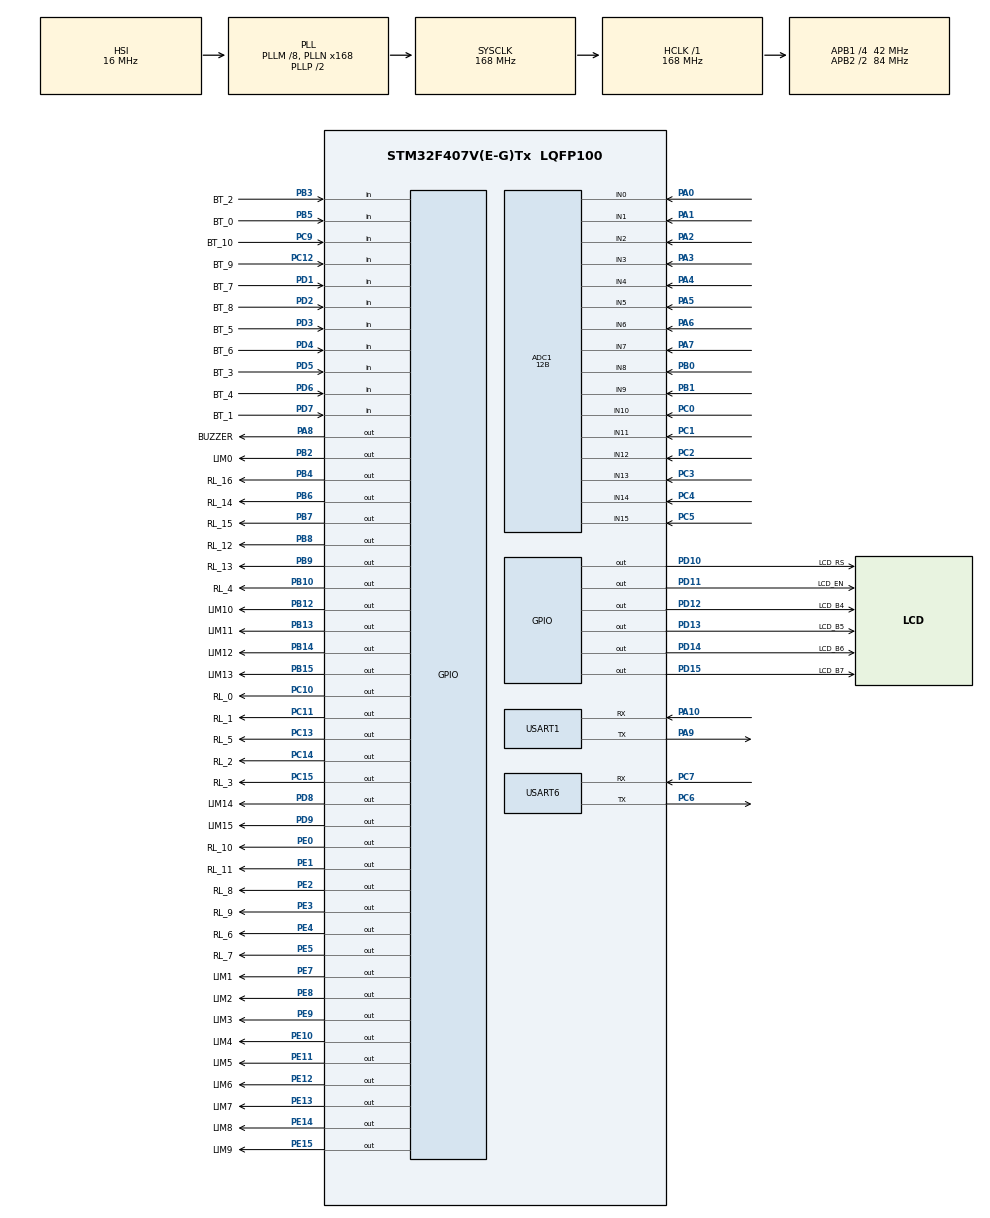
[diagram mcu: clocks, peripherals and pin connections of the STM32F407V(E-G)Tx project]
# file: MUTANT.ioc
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ADC1.Channel-16\#ChannelRegularConversion=ADC_CHANNEL_10
ADC1.Channel-17\#ChannelRegularConversion=ADC_CHANNEL_11
ADC1.Channel-18\#ChannelRegularConversion=ADC_CHANNEL_12
ADC1.Channel-19\#ChannelRegularConversion=ADC_CHANNEL_13
ADC1.Channel-20\#ChannelRegularConversion=ADC_CHANNEL_0
ADC1.Channel-21\#ChannelRegularConversion=ADC_CHANNEL_1
ADC1.Channel-22\#ChannelRegularConversion=ADC_CHANNEL_2
ADC1.Channel-23\#ChannelRegularConversion=ADC_CHANNEL_3
ADC1.Channel-24\#ChannelRegularConversion=ADC_CHANNEL_4
ADC1.Channel-25\#ChannelRegularConversion=ADC_CHANNEL_5
ADC1.Channel-26\#ChannelRegularConversion=ADC_CHANNEL_6
ADC1.Channel-27\#ChannelRegularConversion=ADC_CHANNEL_7
ADC1.Channel-28\#ChannelRegularConversion=ADC_CHANNEL_14
ADC1.Channel-29\#ChannelRegularConversion=ADC_CHANNEL_15
ADC1.Channel-34\#ChannelRegularConversion=ADC_CHANNEL_8
ADC1.Channel-35\#ChannelRegularConversion=ADC_CHANNEL_9
ADC1.ClockPrescaler=ADC_CLOCK_SYNC_PCLK_DIV8
ADC1.ContinuousConvMode=ENABLE
ADC1.DMAContinuousRequests=ENABLE
ADC1.NbrOfConversion=16
ADC1.NbrOfConversionFlag=1
ADC1.Rank-16\#ChannelRegularConversion=1
ADC1.Rank-17\#ChannelRegularConversion=2
ADC1.Rank-18\#ChannelRegularConversion=3
ADC1.Rank-19\#ChannelRegularConversion=4
ADC1.Rank-20\#ChannelRegularConversion=5
ADC1.Rank-21\#ChannelRegularConversion=6
ADC1.Rank-22\#ChannelRegularConversion=7
ADC1.Rank-23\#ChannelRegularConversion=8
ADC1.Rank-24\#ChannelRegularConversion=9
ADC1.Rank-25\#ChannelRegularConversion=10
ADC1.Rank-26\#ChannelRegularConversion=11
ADC1.Rank-27\#ChannelRegularConversion=12
ADC1.Rank-28\#ChannelRegularConversion=13
ADC1.Rank-29\#ChannelRegularConversion=14
ADC1.Rank-34\#ChannelRegularConversion=15
ADC1.Rank-35\#ChannelRegularConversion=16
ADC1.Resolution=ADC_RESOLUTION_12B
ADC1.SamplingTime-16\#ChannelRegularConversion=ADC_SAMPLETIME_480CYCLES
ADC1.SamplingTime-17\#ChannelRegularConversion=ADC_SAMPLETIME_480CYCLES
ADC1.SamplingTime-18\#ChannelRegularConversion=ADC_SAMPLETIME_480CYCLES
ADC1.SamplingTime-19\#ChannelRegularConversion=ADC_SAMPLETIME_480CYCLES
ADC1.SamplingTime-20\#ChannelRegularConversion=ADC_SAMPLETIME_480CYCLES
ADC1.SamplingTime-21\#ChannelRegularConversion=ADC_SAMPLETIME_480CYCLES
ADC1.SamplingTime-22\#ChannelRegularConversion=ADC_SAMPLETIME_480CYCLES
ADC1.SamplingTime-23\#ChannelRegularConversion=ADC_SAMPLETIME_480CYCLES
ADC1.SamplingTime-24\#ChannelRegularConversion=ADC_SAMPLETIME_480CYCLES
ADC1.SamplingTime-25\#ChannelRegularConversion=ADC_SAMPLETIME_480CYCLES
ADC1.SamplingTime-26\#ChannelRegularConversion=ADC_SAMPLETIME_480CYCLES
ADC1.SamplingTime-27\#ChannelRegularConversion=ADC_SAMPLETIME_480CYCLES
ADC1.SamplingTime-28\#ChannelRegularConversion=ADC_SAMPLETIME_480CYCLES
ADC1.SamplingTime-29\#ChannelRegularConversion=ADC_SAMPLETIME_480CYCLES
ADC1.SamplingTime-34\#ChannelRegularConversion=ADC_SAMPLETIME_3CYCLES
ADC1.SamplingTime-35\#ChannelRegularConversion=ADC_SAMPLETIME_3CYCLES
ADC1.ScanConvMode=ENABLE
ADC1.master=1
Dma.ADC1.0.Direction=DMA_PERIPH_TO_MEMORY
Dma.ADC1.0.FIFOMode=DMA_FIFOMODE_DISABLE
Dma.ADC1.0.Instance=DMA2_Stream0
Dma.ADC1.0.MemDataAlignment=DMA_MDATAALIGN_WORD
Dma.ADC1.0.MemInc=DMA_MINC_ENABLE
Dma.ADC1.0.Mode=DMA_CIRCULAR
Dma.ADC1.0.PeriphDataAlignment=DMA_PDATAALIGN_WORD
Dma.ADC1.0.PeriphInc=DMA_PINC_DISABLE
Dma.ADC1.0.Priority=DMA_PRIORITY_LOW
Dma.Request0=ADC1
Dma.Request1=USART1_RX
Dma.Request2=USART6_RX
Dma.USART1_RX.1.Direction=DMA_PERIPH_TO_MEMORY
Dma.USART1_RX.1.FIFOMode=DMA_FIFOMODE_DISABLE
Dma.USART1_RX.1.Instance=DMA2_Stream5
Dma.USART1_RX.1.MemDataAlignment=DMA_MDATAALIGN_BYTE
Dma.USART1_RX.1.MemInc=DMA_MINC_ENABLE
Dma.USART1_RX.1.Mode=DMA_NORMAL
Dma.USART1_RX.1.PeriphDataAlignment=DMA_PDATAALIGN_BYTE
Dma.USART1_RX.1.PeriphInc=DMA_PINC_DISABLE
Dma.USART1_RX.1.Priority=DMA_PRIORITY_LOW
Dma.USART6_RX.2.Direction=DMA_PERIPH_TO_MEMORY
Dma.USART6_RX.2.FIFOMode=DMA_FIFOMODE_DISABLE
Dma.USART6_RX.2.Instance=DMA2_Stream1
Dma.USART6_RX.2.MemDataAlignment=DMA_MDATAALIGN_BYTE
Dma.USART6_RX.2.MemInc=DMA_MINC_ENABLE
Dma.USART6_RX.2.Mode=DMA_NORMAL
Dma.USART6_RX.2.PeriphDataAlignment=DMA_PDATAALIGN_BYTE
Dma.USART6_RX.2.PeriphInc=DMA_PINC_DISABLE
Dma.USART6_RX.2.Priority=DMA_PRIORITY_LOW
Mcu.Family=STM32F4
Mcu.Name=STM32F407V(E-G)Tx
Mcu.Package=LQFP100
NVIC.DMA2_Stream0_IRQn=true\:0\:0\:false\:false\:true\:false\:true
NVIC.DMA2_Stream1_IRQn=true\:0\:0\:false\:false\:true\:false\:true
NVIC.DMA2_Stream5_IRQn=true\:0\:0\:false\:false\:true\:false\:true
NVIC.PriorityGroup=NVIC_PRIORITYGROUP_4
NVIC.USART1_IRQn=true\:0\:0\:false\:false\:true\:true\:true
NVIC.USART6_IRQn=true\:0\:0\:false\:false\:true\:true\:true
PA0-WKUP.Signal=ADCx_IN0
PA1.Signal=ADCx_IN1
PA10.Mode=Asynchronous
PA10.Signal=USART1_RX
PA13.Signal=SYS_JTMS-SWDIO
PA14.Signal=SYS_JTCK-SWCLK
PA2.Signal=ADCx_IN2
PA3.Signal=ADCx_IN3
PA4.Signal=ADCx_IN4
PA5.Signal=ADCx_IN5
PA6.Signal=ADCx_IN6
PA7.Signal=ADCx_IN7
PA8.GPIO_Label=BUZZER
PA8.Signal=GPIO_Output
PA9.Mode=Asynchronous
PA9.Signal=USART1_TX
PB0.Signal=ADCx_IN8
PB1.Signal=ADCx_IN9
PB10.GPIO_Label=RL_4
PB10.Signal=GPIO_Output
PB11.Signal=I2C2_SDA
PB12.GPIO_Label=LIM10
PB12.Signal=GPIO_Output
PB13.GPIO_Label=LIM11
PB13.Signal=GPIO_Output
PB14.GPIO_Label=LIM12
PB14.Signal=GPIO_Output
PB15.GPIO_Label=LIM13
PB15.Signal=GPIO_Output
PB2.GPIO_Label=LIM0
PB2.Signal=GPIO_Output
PB3.GPIO_Label=BT_2
PB3.GPIO_PuPd=GPIO_PULLUP
PB3.Signal=GPIO_Input
PB4.GPIO_Label=RL_16
PB4.Signal=GPIO_Output
PB5.GPIO_Label=BT_0
PB5.GPIO_PuPd=GPIO_PULLUP
PB5.Signal=GPIO_Input
PB6.GPIO_Label=RL_14
PB6.Signal=GPIO_Output
PB7.GPIO_Label=RL_15
PB7.Signal=GPIO_Output
PB8.GPIO_Label=RL_12
PB8.Signal=GPIO_Output
PB9.GPIO_Label=RL_13
PB9.Signal=GPIO_Output
PC0.Signal=ADCx_IN10
PC1.Signal=ADCx_IN11
PC10.GPIO_Label=RL_0
PC10.Signal=GPIO_Output
PC11.GPIO_Label=RL_1
PC11.Signal=GPIO_Output
PC12.GPIO_Label=BT_9
PC12.GPIO_PuPd=GPIO_PULLUP
PC12.Signal=GPIO_Input
PC13-ANTI_TAMP.GPIO_Label=RL_5
PC13-ANTI_TAMP.Signal=GPIO_Output
PC14-OSC32_IN.GPIO_Label=RL_2
PC14-OSC32_IN.Signal=GPIO_Output
PC15-OSC32_OUT.GPIO_Label=RL_3
PC15-OSC32_OUT.Signal=GPIO_Output
PC2.Signal=ADCx_IN12
PC3.Signal=ADCx_IN13
PC4.Signal=ADCx_IN14
PC5.Signal=ADCx_IN15
PC6.Mode=Asynchronous
PC6.Signal=USART6_TX
PC7.Mode=Asynchronous
PC7.Signal=USART6_RX
PC8.Signal=USART6_CK
PC9.GPIO_Label=BT_10
PC9.GPIO_PuPd=GPIO_PULLUP
PC9.Signal=GPIO_Input
PD1.GPIO_Label=BT_7
PD1.GPIO_PuPd=GPIO_PULLUP
PD1.Signal=GPIO_Input
PD10.GPIO_Label=LCD_RS
PD10.Signal=GPIO_Output
PD11.GPIO_Label=LCD_EN
PD11.Signal=GPIO_Output
PD12.GPIO_Label=LCD_B4
PD12.Signal=GPIO_Output
PD13.GPIO_Label=LCD_B5
PD13.Signal=GPIO_Output
PD14.GPIO_Label=LCD_B6
PD14.Signal=GPIO_Output
PD15.GPIO_Label=LCD_B7
PD15.Signal=GPIO_Output
PD2.GPIO_Label=BT_8
PD2.GPIO_PuPd=GPIO_PULLUP
PD2.Signal=GPIO_Input
PD3.GPIO_Label=BT_5
PD3.GPIO_PuPd=GPIO_PULLUP
PD3.Signal=GPIO_Input
PD4.GPIO_Label=BT_6
PD4.GPIO_PuPd=GPIO_PULLUP
PD4.Signal=GPIO_Input
PD5.GPIO_Label=BT_3
PD5.GPIO_PuPd=GPIO_PULLUP
PD5.Signal=GPIO_Input
PD6.GPIO_Label=BT_4
PD6.GPIO_PuPd=GPIO_PULLUP
PD6.Signal=GPIO_Input
PD7.GPIO_Label=BT_1
PD7.GPIO_PuPd=GPIO_PULLUP
PD7.Signal=GPIO_Input
PD8.GPIO_Label=LIM14
PD8.Signal=GPIO_Output
PD9.GPIO_Label=LIM15
PD9.Signal=GPIO_Output
PE0.GPIO_Label=RL_10
PE0.Signal=GPIO_Output
PE1.GPIO_Label=RL_11
PE1.Signal=GPIO_Output
PE10.GPIO_Label=LIM4
PE10.Signal=GPIO_Output
PE11.GPIO_Label=LIM5
PE11.Signal=GPIO_Output
PE12.GPIO_Label=LIM6
PE12.Signal=GPIO_Output
PE13.GPIO_Label=LIM7
PE13.Signal=GPIO_Output
PE14.GPIO_Label=LIM8
PE14.Signal=GPIO_Output
PE15.GPIO_Label=LIM9
PE15.Signal=GPIO_Output
PE2.GPIO_Label=RL_8
PE2.Signal=GPIO_Output
PE3.GPIO_Label=RL_9
PE3.Signal=GPIO_Output
PE4.GPIO_Label=RL_6
PE4.Signal=GPIO_Output
PE5.GPIO_Label=RL_7
PE5.Signal=GPIO_Output
PE7.GPIO_Label=LIM1
PE7.Signal=GPIO_Output
PE8.GPIO_Label=LIM2
PE8.Signal=GPIO_Output
PE9.GPIO_Label=LIM3
PE9.Signal=GPIO_Output
ProjectManager.HeapSize=0x200
ProjectManager.StackSize=0x400
ProjectManager.TargetToolchain=MDK-ARM V5.32
RCC.48MHZClocksFreq_Value=84000000
RCC.AHBFreq_Value=168000000
RCC.APB1CLKDivider=RCC_HCLK_DIV4
RCC.APB1Freq_Value=42000000
RCC.APB1TimFreq_Value=84000000
RCC.APB2CLKDivider=RCC_HCLK_DIV2
RCC.APB2Freq_Value=84000000
RCC.APB2TimFreq_Value=168000000
RCC.CortexFreq_Value=168000000
RCC.HCLKFreq_Value=168000000
RCC.HSE_VALUE=25000000
RCC.HSI_VALUE=16000000
RCC.LSE_VALUE=32768
RCC.PLLM=8
RCC.PLLN=168
RCC.SYSCLKFreq_VALUE=168000000
RCC.SYSCLKSource=RCC_SYSCLKSOURCE_PLLCLK
RCC.VCOOutputFreq_Value=336000000
SH.ADCx_IN0.0=ADC1_IN0,IN0
SH.ADCx_IN1.0=ADC1_IN1,IN1
SH.ADCx_IN10.0=ADC1_IN10,IN10
SH.ADCx_IN11.0=ADC1_IN11,IN11
SH.ADCx_IN12.0=ADC1_IN12,IN12
SH.ADCx_IN13.0=ADC1_IN13,IN13
SH.ADCx_IN14.0=ADC1_IN14,IN14
SH.ADCx_IN15.0=ADC1_IN15,IN15
SH.ADCx_IN2.0=ADC1_IN2,IN2
SH.ADCx_IN3.0=ADC1_IN3,IN3
SH.ADCx_IN4.0=ADC1_IN4,IN4
SH.ADCx_IN5.0=ADC1_IN5,IN5
SH.ADCx_IN6.0=ADC1_IN6,IN6
SH.ADCx_IN7.0=ADC1_IN7,IN7
SH.ADCx_IN8.0=ADC1_IN8,IN8
SH.ADCx_IN9.0=ADC1_IN9,IN9
USART1.VirtualMode=VM_ASYNC
USART6.VirtualMode=VM_ASYNC
board=custom

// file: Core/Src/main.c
/* USER CODE BEGIN Header */
/**
  ******************************************************************************
  * @file           : main.c
  * @brief          : Main program body
  ******************************************************************************
  * @attention
  *
  * <h2><center>&copy; Copyright (c) 2021 STMicroelectronics.
  * All rights reserved.</center></h2>
  *
  * This software component is licensed by ST under BSD 3-Clause license,
  * the "License"; You may not use this file except in compliance with the
  * License. You may obtain a copy of the License at:
  *                        opensource.org/licenses/BSD-3-Clause
  *
  ******************************************************************************
  */
/* USER CODE END Header */
#include "main.h"

/* USER CODE BEGIN Includes */
#include "stdbool.h"
#include "stdio.h"
#include "LCD_Lib.h"
#include "Header.h"
#include "String.h"
#include "DWT_Delay.h"
/* USER CODE END Includes */

/* USER CODE BEGIN PD */
#define USART_BUF_SIZE 128
/* USER CODE END PD */

ADC_HandleTypeDef hadc1;
DMA_HandleTypeDef hdma_adc1;

UART_HandleTypeDef huart1;
UART_HandleTypeDef huart6;
DMA_HandleTypeDef hdma_usart1_rx;
DMA_HandleTypeDef hdma_usart6_rx;

/* USER CODE BEGIN PV */
uint8_t USART_pBuffer[USART_BUF_SIZE * 2];
uint8_t stringBuffer[USART_BUF_SIZE];
bool USART_status = false;
char bufferr[128];
uint32_t adcBuffer[16];
bool systemSetOK = false;
/* USER CODE END PV */

void SystemClock_Config(void);
static void MX_GPIO_Init(void);
static void MX_USART1_UART_Init(void);
static void MX_USART6_UART_Init(void);
static void MX_DMA_Init(void);
static void MX_ADC1_Init(void);

/* USER CODE BEGIN 0 */
/*#include "main.h"
#include "stdbool.h"
#include "stdio.h"
#include "LCD_Lib.h"
#include "Header.h"
#include "String.h"
#include "DWT_Delay.h"
*/
/* USER CODE END 0 */

int main(void)
{

  /* MCU Configuration--------------------------------------------------------*/

  /* Reset of all peripherals, Initializes the Flash interface and the Systick. */
  HAL_Init();

  /* Configure the system clock */
  SystemClock_Config();

  /* Initialize all configured peripherals */
  MX_GPIO_Init();
	MX_DMA_Init();
  MX_USART1_UART_Init();
  MX_USART6_UART_Init();
  MX_ADC1_Init();
  /* USER CODE BEGIN 2 */
	HAL_ADC_Start_DMA(&hadc1, adcBuffer, 16);
	HAL_UARTEx_ReceiveToIdle_DMA(&huart1, USART_pBuffer, USART_BUF_SIZE);
	__HAL_DMA_DISABLE_IT(&hdma_usart1_rx, DMA_IT_HT);
//	__HAL_UART_ENABLE_IT(&huart6, UART_IT_RXNE);
	LCD_Init(40,2);
	LCD_CursorSet(0,0);
	LCD_Putsxy(0, 0,"====> MUTANT 2.0 <====");
	LCD_Putsxy(0, 1,"==> FIRE ALARM <==");
	DWT_Delayms(1000);
	LCD_Clear();
	int increm = 0;
  /* USER CODE END 2 */

  /* Infinite loop */
  while (1)
  {
		if(systemSetOK == false){
			while(1){
				if(systemSetOK == false){
					systemSetOK =  selectMenu();
					LCD_Clear();
				}else{
					sprintf(bufferr, "MODE %d || INT %d", selectedSensingMode, valueSetInterval);
					LCD_Putsxy(0,0, "SYSTEM RUNNING");
					LCD_Putsxy(0,1, bufferr);
					sendDateTime();
					if(flagRx == true){parsingDataF1();}					//Parsing DATA
					DWT_Delayms(2000);
					LCD_Clear();
					break;
				}
			}
		}else{
		// JALANKAN PROGRAM RUNNING SYSTEM IN HERE
			if(selectedSensingMode == 1){
				LCD_Putsxy(14,0, "MUTANT 2.0");
				LCD_Putsxy(10, 1, dateTime);
				if(flagRx == true){parsingDataF1();}					//Parsing DATA
				modeSingleWire();
				//checkSortAndOpenCircuit();
				//checkSupply();
			}else if(selectedSensingMode == 2){
				LCD_Putsxy(14,0, "MUTANT 2.0");
				LCD_Putsxy(10, 1, dateTime);
				if(flagRx == true){parsingDataF1();}					//Parsing DATA
				modeCrossWire();
				//checkSortAndOpenCircuit();
				//checkSupply();
			}
		}
		 //UNTUK TEST UART
	/*
		if(USART_status == false){
			sendDateTime();
			USART_status = true;
		}

		if(USART_status == true){
			if(increm >= 0 && increm <= 100){
				sendDataSegment();
			}else if(increm > 100 && increm <= 200){
				sendDataSegment2();
			}else if(increm > 200 && increm <= 300){
				sendDataSegment3();
			} else if(increm > 300){
				increm = 0;
			}
			increm++;
			HAL_Delay(1000);
		}
		*/
//		  if(flagRx == true){
//				sprintf(bufferr, "Received :  %s \r\n", stringBuffer);
//				HAL_UART_Transmit(&huart6,(uint8_t *) bufferr, strlen(bufferr), 100);

//				parsingDataF1();					//Parsing stringBuffer
//	  }

  }
}

void SystemClock_Config(void)
{
  RCC_OscInitTypeDef RCC_OscInitStruct = {0};
  RCC_ClkInitTypeDef RCC_ClkInitStruct = {0};

  /** Configure the main internal regulator output voltage
  */
  __HAL_RCC_PWR_CLK_ENABLE();
  __HAL_PWR_VOLTAGESCALING_CONFIG(PWR_REGULATOR_VOLTAGE_SCALE1);
  /** Initializes the RCC Oscillators according to the specified parameters
  * in the RCC_OscInitTypeDef structure.
  */
  RCC_OscInitStruct.OscillatorType = RCC_OSCILLATORTYPE_HSI;
  RCC_OscInitStruct.HSIState = RCC_HSI_ON;
  RCC_OscInitStruct.HSICalibrationValue = RCC_HSICALIBRATION_DEFAULT;
  RCC_OscInitStruct.PLL.PLLState = RCC_PLL_ON;
  RCC_OscInitStruct.PLL.PLLSource = RCC_PLLSOURCE_HSI;
  RCC_OscInitStruct.PLL.PLLM = 8;
  RCC_OscInitStruct.PLL.PLLN = 168;
  RCC_OscInitStruct.PLL.PLLP = RCC_PLLP_DIV2;
  RCC_OscInitStruct.PLL.PLLQ = 4;
  if (HAL_RCC_OscConfig(&RCC_OscInitStruct) != HAL_OK)
  {
    Error_Handler();
  }
  /** Initializes the CPU, AHB and APB buses clocks
  */
  RCC_ClkInitStruct.ClockType = RCC_CLOCKTYPE_HCLK|RCC_CLOCKTYPE_SYSCLK
                              |RCC_CLOCKTYPE_PCLK1|RCC_CLOCKTYPE_PCLK2;
  RCC_ClkInitStruct.SYSCLKSource = RCC_SYSCLKSOURCE_PLLCLK;
  RCC_ClkInitStruct.AHBCLKDivider = RCC_SYSCLK_DIV1;
  RCC_ClkInitStruct.APB1CLKDivider = RCC_HCLK_DIV4;
  RCC_ClkInitStruct.APB2CLKDivider = RCC_HCLK_DIV2;

  if (HAL_RCC_ClockConfig(&RCC_ClkInitStruct, FLASH_LATENCY_5) != HAL_OK)
  {
    Error_Handler();
  }
}

static void MX_ADC1_Init(void)
{

  ADC_ChannelConfTypeDef sConfig = {0};

  /** Configure the global features of the ADC (Clock, Resolution, Data Alignment and number of conversion)
  */
  hadc1.Instance = ADC1;
  hadc1.Init.ClockPrescaler = ADC_CLOCK_SYNC_PCLK_DIV8;
  hadc1.Init.Resolution = ADC_RESOLUTION_12B;
  hadc1.Init.ScanConvMode = ENABLE;
  hadc1.Init.ContinuousConvMode = ENABLE;
  hadc1.Init.DiscontinuousConvMode = DISABLE;
  hadc1.Init.ExternalTrigConvEdge = ADC_EXTERNALTRIGCONVEDGE_NONE;
  hadc1.Init.ExternalTrigConv = ADC_SOFTWARE_START;
  hadc1.Init.DataAlign = ADC_DATAALIGN_RIGHT;
  hadc1.Init.NbrOfConversion = 16;
  hadc1.Init.DMAContinuousRequests = ENABLE;
  hadc1.Init.EOCSelection = ADC_EOC_SINGLE_CONV;
  if (HAL_ADC_Init(&hadc1) != HAL_OK)
  {
    Error_Handler();
  }
  /** Configure for the selected ADC regular channel its corresponding rank in the sequencer and its sample time.
  */
  sConfig.Channel = ADC_CHANNEL_10;
  sConfig.Rank = 1;
  sConfig.SamplingTime = ADC_SAMPLETIME_480CYCLES;
  if (HAL_ADC_ConfigChannel(&hadc1, &sConfig) != HAL_OK)
  {
    Error_Handler();
  }
  /** Configure for the selected ADC regular channel its corresponding rank in the sequencer and its sample time.
  */
  sConfig.Channel = ADC_CHANNEL_11;
  sConfig.Rank = 2;
  if (HAL_ADC_ConfigChannel(&hadc1, &sConfig) != HAL_OK)
  {
    Error_Handler();
  }
  /** Configure for the selected ADC regular channel its corresponding rank in the sequencer and its sample time.
  */
  sConfig.Channel = ADC_CHANNEL_12;
  sConfig.Rank = 3;
  if (HAL_ADC_ConfigChannel(&hadc1, &sConfig) != HAL_OK)
  {
    Error_Handler();
  }
  /** Configure for the selected ADC regular channel its corresponding rank in the sequencer and its sample time.
  */
  sConfig.Channel = ADC_CHANNEL_13;
  sConfig.Rank = 4;
  if (HAL_ADC_ConfigChannel(&hadc1, &sConfig) != HAL_OK)
  {
    Error_Handler();
  }
  /** Configure for the selected ADC regular channel its corresponding rank in the sequencer and its sample time.
  */
  sConfig.Channel = ADC_CHANNEL_0;
  sConfig.Rank = 5;
  if (HAL_ADC_ConfigChannel(&hadc1, &sConfig) != HAL_OK)
  {
    Error_Handler();
  }
  /** Configure for the selected ADC regular channel its corresponding rank in the sequencer and its sample time.
  */
  sConfig.Channel = ADC_CHANNEL_1;
  sConfig.Rank = 6;
  if (HAL_ADC_ConfigChannel(&hadc1, &sConfig) != HAL_OK)
  {
    Error_Handler();
  }
  /** Configure for the selected ADC regular channel its corresponding rank in the sequencer and its sample time.
  */
  sConfig.Channel = ADC_CHANNEL_2;
  sConfig.Rank = 7;
  if (HAL_ADC_ConfigChannel(&hadc1, &sConfig) != HAL_OK)
  {
    Error_Handler();
  }
  /** Configure for the selected ADC regular channel its corresponding rank in the sequencer and its sample time.
  */
  sConfig.Channel = ADC_CHANNEL_3;
  sConfig.Rank = 8;
  if (HAL_ADC_ConfigChannel(&hadc1, &sConfig) != HAL_OK)
  {
    Error_Handler();
  }
  /** Configure for the selected ADC regular channel its corresponding rank in the sequencer and its sample time.
  */
  sConfig.Channel = ADC_CHANNEL_4;
  sConfig.Rank = 9;
  if (HAL_ADC_ConfigChannel(&hadc1, &sConfig) != HAL_OK)
  {
    Error_Handler();
  }
  /** Configure for the selected ADC regular channel its corresponding rank in the sequencer and its sample time.
  */
  sConfig.Channel = ADC_CHANNEL_5;
  sConfig.Rank = 10;
  if (HAL_ADC_ConfigChannel(&hadc1, &sConfig) != HAL_OK)
  {
    Error_Handler();
  }
  /** Configure for the selected ADC regular channel its corresponding rank in the sequencer and its sample time.
  */
  sConfig.Channel = ADC_CHANNEL_6;
  sConfig.Rank = 11;
  if (HAL_ADC_ConfigChannel(&hadc1, &sConfig) != HAL_OK)
  {
    Error_Handler();
  }
  /** Configure for the selected ADC regular channel its corresponding rank in the sequencer and its sample time.
  */
  sConfig.Channel = ADC_CHANNEL_7;
  sConfig.Rank = 12;
  if (HAL_ADC_ConfigChannel(&hadc1, &sConfig) != HAL_OK)
  {
    Error_Handler();
  }
  /** Configure for the selected ADC regular channel its corresponding rank in the sequencer and its sample time.
  */
  sConfig.Channel = ADC_CHANNEL_14;
  sConfig.Rank = 13;
  if (HAL_ADC_ConfigChannel(&hadc1, &sConfig) != HAL_OK)
  {
    Error_Handler();
  }
  /** Configure for the selected ADC regular channel its corresponding rank in the sequencer and its sample time.
  */
  sConfig.Channel = ADC_CHANNEL_15;
  sConfig.Rank = 14;
  if (HAL_ADC_ConfigChannel(&hadc1, &sConfig) != HAL_OK)
  {
    Error_Handler();
  }
  /** Configure for the selected ADC regular channel its corresponding rank in the sequencer and its sample time.
  */
  sConfig.Channel = ADC_CHANNEL_8;
  sConfig.Rank = 15;
  sConfig.SamplingTime = ADC_SAMPLETIME_3CYCLES;
  if (HAL_ADC_ConfigChannel(&hadc1, &sConfig) != HAL_OK)
  {
    Error_Handler();
  }
  /** Configure for the selected ADC regular channel its corresponding rank in the sequencer and its sample time.
  */
  sConfig.Channel = ADC_CHANNEL_9;
  sConfig.Rank = 16;
  if (HAL_ADC_ConfigChannel(&hadc1, &sConfig) != HAL_OK)
  {
    Error_Handler();
  }

}

static void MX_USART1_UART_Init(void)
{

  huart1.Instance = USART1;
  huart1.Init.BaudRate = 115200;
  huart1.Init.WordLength = UART_WORDLENGTH_8B;
  huart1.Init.StopBits = UART_STOPBITS_1;
  huart1.Init.Parity = UART_PARITY_NONE;
  huart1.Init.Mode = UART_MODE_TX_RX;
  huart1.Init.HwFlowCtl = UART_HWCONTROL_NONE;
  huart1.Init.OverSampling = UART_OVERSAMPLING_16;
  if (HAL_UART_Init(&huart1) != HAL_OK)
  {
    Error_Handler();
  }

}

static void MX_USART6_UART_Init(void)
{

  huart6.Instance = USART6;
  huart6.Init.BaudRate = 115200;
  huart6.Init.WordLength = UART_WORDLENGTH_8B;
  huart6.Init.StopBits = UART_STOPBITS_1;
  huart6.Init.Parity = UART_PARITY_NONE;
  huart6.Init.Mode = UART_MODE_TX_RX;
  huart6.Init.HwFlowCtl = UART_HWCONTROL_NONE;
  huart6.Init.OverSampling = UART_OVERSAMPLING_16;
  if (HAL_UART_Init(&huart6) != HAL_OK)
  {
    Error_Handler();
  }

}

static void MX_DMA_Init(void)
{

  /* DMA controller clock enable */
  __HAL_RCC_DMA2_CLK_ENABLE();

  /* DMA interrupt init */
  /* DMA2_Stream0_IRQn interrupt configuration */
  HAL_NVIC_SetPriority(DMA2_Stream0_IRQn, 0, 0);
  HAL_NVIC_EnableIRQ(DMA2_Stream0_IRQn);
  /* DMA2_Stream1_IRQn interrupt configuration */
  HAL_NVIC_SetPriority(DMA2_Stream1_IRQn, 0, 0);
  HAL_NVIC_EnableIRQ(DMA2_Stream1_IRQn);
  /* DMA2_Stream5_IRQn interrupt configuration */
  HAL_NVIC_SetPriority(DMA2_Stream5_IRQn, 0, 0);
  HAL_NVIC_EnableIRQ(DMA2_Stream5_IRQn);

}

static void MX_GPIO_Init(void)
{
  GPIO_InitTypeDef GPIO_InitStruct = {0};

  /* GPIO Ports Clock Enable */
  __HAL_RCC_GPIOE_CLK_ENABLE();
  __HAL_RCC_GPIOC_CLK_ENABLE();
  __HAL_RCC_GPIOA_CLK_ENABLE();
  __HAL_RCC_GPIOB_CLK_ENABLE();
  __HAL_RCC_GPIOD_CLK_ENABLE();

  /*Configure GPIO pin Output Level */
  HAL_GPIO_WritePin(GPIOE, RL_8_Pin|RL_9_Pin|RL_6_Pin|RL_7_Pin
                          |LIM1_Pin|LIM2_Pin|LIM3_Pin|LIM4_Pin
                          |LIM5_Pin|LIM6_Pin|LIM7_Pin|LIM8_Pin
                          |LIM9_Pin|RL_10_Pin|RL_11_Pin, GPIO_PIN_RESET);

  /*Configure GPIO pin Output Level */
  HAL_GPIO_WritePin(GPIOC, RL_5_Pin|RL_2_Pin|RL_3_Pin|RL_0_Pin
                          |RL_1_Pin, GPIO_PIN_RESET);

  /*Configure GPIO pin Output Level */
  HAL_GPIO_WritePin(GPIOB, LIM0_Pin|RL_4_Pin|LIM10_Pin|LIM11_Pin
                          |LIM12_Pin|LIM13_Pin|RL_16_Pin|RL_14_Pin
                          |RL_15_Pin|RL_12_Pin|RL_13_Pin, GPIO_PIN_RESET);

  /*Configure GPIO pin Output Level */
  HAL_GPIO_WritePin(GPIOD, LIM14_Pin|LIM15_Pin|LCD_RS_Pin|LCD_EN_Pin
                          |LCD_B4_Pin|LCD_B5_Pin|LCD_B6_Pin|LCD_B7_Pin, GPIO_PIN_RESET);

  /*Configure GPIO pin Output Level */
  HAL_GPIO_WritePin(BUZZER_GPIO_Port, BUZZER_Pin, GPIO_PIN_RESET);

  /*Configure GPIO pins : RL_8_Pin RL_9_Pin RL_6_Pin RL_7_Pin
                           LIM1_Pin LIM2_Pin LIM3_Pin LIM4_Pin
                           LIM5_Pin LIM6_Pin LIM7_Pin LIM8_Pin
                           LIM9_Pin RL_10_Pin RL_11_Pin */
  GPIO_InitStruct.Pin = RL_8_Pin|RL_9_Pin|RL_6_Pin|RL_7_Pin
                          |LIM1_Pin|LIM2_Pin|LIM3_Pin|LIM4_Pin
                          |LIM5_Pin|LIM6_Pin|LIM7_Pin|LIM8_Pin
                          |LIM9_Pin|RL_10_Pin|RL_11_Pin;
  GPIO_InitStruct.Mode = GPIO_MODE_OUTPUT_PP;
  GPIO_InitStruct.Pull = GPIO_NOPULL;
  GPIO_InitStruct.Speed = GPIO_SPEED_FREQ_LOW;
  HAL_GPIO_Init(GPIOE, &GPIO_InitStruct);

  /*Configure GPIO pins : RL_5_Pin RL_2_Pin RL_3_Pin RL_0_Pin
                           RL_1_Pin */
  GPIO_InitStruct.Pin = RL_5_Pin|RL_2_Pin|RL_3_Pin|RL_0_Pin
                          |RL_1_Pin;
  GPIO_InitStruct.Mode = GPIO_MODE_OUTPUT_PP;
  GPIO_InitStruct.Pull = GPIO_NOPULL;
  GPIO_InitStruct.Speed = GPIO_SPEED_FREQ_LOW;
  HAL_GPIO_Init(GPIOC, &GPIO_InitStruct);

  /*Configure GPIO pins : LIM0_Pin RL_4_Pin LIM10_Pin LIM11_Pin
                           LIM12_Pin LIM13_Pin RL_16_Pin RL_14_Pin
                           RL_15_Pin RL_12_Pin RL_13_Pin */
  GPIO_InitStruct.Pin = LIM0_Pin|RL_4_Pin|LIM10_Pin|LIM11_Pin
                          |LIM12_Pin|LIM13_Pin|RL_16_Pin|RL_14_Pin
                          |RL_15_Pin|RL_12_Pin|RL_13_Pin;
  GPIO_InitStruct.Mode = GPIO_MODE_OUTPUT_PP;
  GPIO_InitStruct.Pull = GPIO_NOPULL;
  GPIO_InitStruct.Speed = GPIO_SPEED_FREQ_LOW;
  HAL_GPIO_Init(GPIOB, &GPIO_InitStruct);

  /*Configure GPIO pin : PB11 */
  GPIO_InitStruct.Pin = GPIO_PIN_11;
  GPIO_InitStruct.Mode = GPIO_MODE_AF_OD;
  GPIO_InitStruct.Pull = GPIO_NOPULL;
  GPIO_InitStruct.Speed = GPIO_SPEED_FREQ_VERY_HIGH;
  GPIO_InitStruct.Alternate = GPIO_AF4_I2C2;
  HAL_GPIO_Init(GPIOB, &GPIO_InitStruct);

  /*Configure GPIO pins : LIM14_Pin LIM15_Pin LCD_RS_Pin LCD_EN_Pin
                           LCD_B4_Pin LCD_B5_Pin LCD_B6_Pin LCD_B7_Pin */
  GPIO_InitStruct.Pin = LIM14_Pin|LIM15_Pin|LCD_RS_Pin|LCD_EN_Pin
                          |LCD_B4_Pin|LCD_B5_Pin|LCD_B6_Pin|LCD_B7_Pin;
  GPIO_InitStruct.Mode = GPIO_MODE_OUTPUT_PP;
  GPIO_InitStruct.Pull = GPIO_NOPULL;
  GPIO_InitStruct.Speed = GPIO_SPEED_FREQ_LOW;
  HAL_GPIO_Init(GPIOD, &GPIO_InitStruct);

  /*Configure GPIO pins : BT_10_Pin BT_9_Pin */
  GPIO_InitStruct.Pin = BT_10_Pin|BT_9_Pin;
  GPIO_InitStruct.Mode = GPIO_MODE_INPUT;
  GPIO_InitStruct.Pull = GPIO_PULLUP;
  HAL_GPIO_Init(GPIOC, &GPIO_InitStruct);

  /*Configure GPIO pin : BUZZER_Pin */
  GPIO_InitStruct.Pin = BUZZER_Pin;
  GPIO_InitStruct.Mode = GPIO_MODE_OUTPUT_PP;
  GPIO_InitStruct.Pull = GPIO_NOPULL;
  GPIO_InitStruct.Speed = GPIO_SPEED_FREQ_LOW;
  HAL_GPIO_Init(BUZZER_GPIO_Port, &GPIO_InitStruct);

  /*Configure GPIO pins : BT_7_Pin BT_8_Pin BT_5_Pin BT_6_Pin
                           BT_3_Pin BT_4_Pin BT_1_Pin */
  GPIO_InitStruct.Pin = BT_7_Pin|BT_8_Pin|BT_5_Pin|BT_6_Pin
                          |BT_3_Pin|BT_4_Pin|BT_1_Pin;
  GPIO_InitStruct.Mode = GPIO_MODE_INPUT;
  GPIO_InitStruct.Pull = GPIO_PULLUP;
  HAL_GPIO_Init(GPIOD, &GPIO_InitStruct);

  /*Configure GPIO pins : BT_2_Pin BT_0_Pin */
  GPIO_InitStruct.Pin = BT_2_Pin|BT_0_Pin;
  GPIO_InitStruct.Mode = GPIO_MODE_INPUT;
  GPIO_InitStruct.Pull = GPIO_PULLUP;
  HAL_GPIO_Init(GPIOB, &GPIO_InitStruct);

}

/* USER CODE BEGIN 4 */
void HAL_UARTEx_RxEventCallback(UART_HandleTypeDef *huart, uint16_t Size)
{
	if(huart->Instance == USART1){
		memcpy(stringBuffer, USART_pBuffer, Size);
		memcpy(tx, stringBuffer, Size);
		flagRx = true;		// FLAG

		HAL_UARTEx_ReceiveToIdle_DMA(&huart1, USART_pBuffer, USART_BUF_SIZE);
		__HAL_DMA_DISABLE_IT(&hdma_usart1_rx, DMA_IT_HT);
	}
}
/*
void HAL_UART_RxCpltCallback(UART_HandleTypeDef *huart){
	// TODO HERE RXCPT DMA
//	$10-2-2022, 14:58 WIB|101|;
	UNUSED(huart);
	switch(rx_buff)
	{
		case ';':
			for(int countt=0; countt < i; countt++){
				 memset(tmp2, 0, sizeof(tmp2) * (sizeof tmp2[countt]) );
				//memset(tmp2, 0, sizeof(tmp2));
			}
			strncpy(tmp2, Rx, i);
			flagRx = true;
			i =0;
			break;
		default: Rx[i++] = rx_buff;
	}
	//HAL_UART_Receive_DMA(&huart1, &rx_buff, sizeof(rx_buff));
}
void HAL_UART_TxCpltCallback(UART_HandleTypeDef *huart){
	UNUSED(huart);
	//__NOP();
}
*/
/* USER CODE END 4 */

void Error_Handler(void)
{
  __disable_irq();
  while (1)
  {
  }
}

/************************ (C) COPYRIGHT STMicroelectronics *****END OF FILE****/
